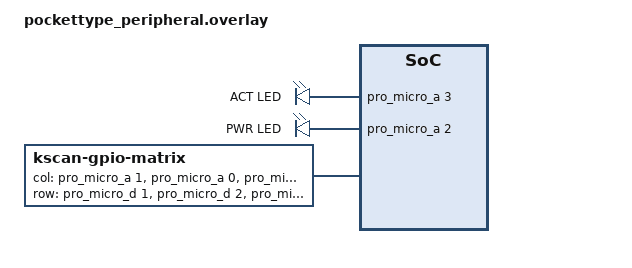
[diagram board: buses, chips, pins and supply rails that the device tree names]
/*
 * Copyright (c) 2020 The ZMK Contributors
 *
 * SPDX-License-Identifier: MIT
 */

#include <dt-bindings/zmk/matrix_transform.h>

#include "pockettype_dongle.overlay"

&default_transform {
    col-offset = <1>;
};

/ {
	leds {
		compatible = "gpio-leds";
		actled: led_a {
			gpios = <&pro_micro_a 3 GPIO_ACTIVE_HIGH>;
			label = "ACT LED";
		};
		powerled: led_p {
			gpios = <&pro_micro_a 2 GPIO_ACTIVE_HIGH>;
			label = "PWR LED";
		};
	};

	kscan0: kscan {
		compatible = "zmk,kscan-gpio-matrix";
		label = "KSCAN";

		diode-direction = "col2row";

		col-gpios
			= <&pro_micro_a 1 GPIO_ACTIVE_HIGH>
			, <&pro_micro_a 0 GPIO_ACTIVE_HIGH>
			, <&pro_micro_d 15 GPIO_ACTIVE_HIGH>
			, <&pro_micro_d 14 GPIO_ACTIVE_HIGH>
			, <&pro_micro_d 16 GPIO_ACTIVE_HIGH>
			, <&pro_micro_d 10 GPIO_ACTIVE_HIGH>
			, <&pro_micro_d 8 GPIO_ACTIVE_HIGH>
			, <&pro_micro_d 7 GPIO_ACTIVE_HIGH>
			, <&pro_micro_d 5 GPIO_ACTIVE_HIGH>
			, <&pro_micro_d 4 GPIO_ACTIVE_HIGH>
			, <&pro_micro_d 3 GPIO_ACTIVE_HIGH>
			, <&pro_micro_d 0 GPIO_ACTIVE_HIGH>
			;

		row-gpios
			= <&pro_micro_d 1 (GPIO_ACTIVE_HIGH | GPIO_PULL_DOWN)>
			, <&pro_micro_d 2 (GPIO_ACTIVE_HIGH | GPIO_PULL_DOWN)>
			, <&pro_micro_d 6 (GPIO_ACTIVE_HIGH | GPIO_PULL_DOWN)>
			, <&pro_micro_d 9 (GPIO_ACTIVE_HIGH | GPIO_PULL_DOWN)>
			;
	};

    chosen {
		zmk,kscan = &kscan0;
		zmk,matrix_transform = &default_transform;
	};
};
